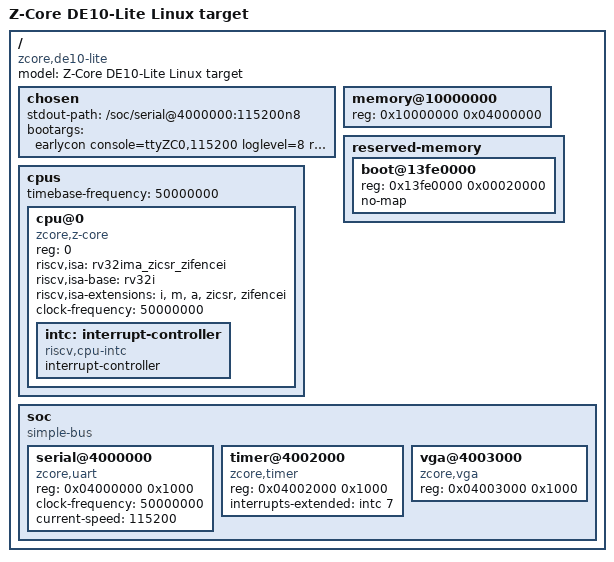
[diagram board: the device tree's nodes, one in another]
/dts-v1/;
/ {
	model = "Z-Core DE10-Lite Linux target";
	compatible = "zcore,de10-lite";
	#address-cells = <1>;
	#size-cells = <1>;
	chosen {
		stdout-path = "/soc/serial@4000000:115200n8";
		bootargs = "earlycon console=ttyZC0,115200 loglevel=8 rdinit=/init";
	};
	memory@10000000 { device_type = "memory"; reg = <0x10000000 0x04000000>; };
	reserved-memory {
		#address-cells = <1>;
		#size-cells = <1>;
		ranges;
		boot@13fe0000 { reg = <0x13fe0000 0x00020000>; no-map; };
	};
	cpus {
		#address-cells = <1>;
		#size-cells = <0>;
		timebase-frequency = <50000000>;
		cpu@0 {
			device_type = "cpu";
			compatible = "zcore,z-core", "riscv";
			reg = <0>;
			status = "okay";
			riscv,isa = "rv32ima_zicsr_zifencei";
			riscv,isa-base = "rv32i";
			riscv,isa-extensions = "i", "m", "a", "zicsr", "zifencei";
			clock-frequency = <50000000>;
			intc: interrupt-controller {
				compatible = "riscv,cpu-intc";
				interrupt-controller;
				#interrupt-cells = <1>;
				#address-cells = <0>;
			};
		};
	};
	soc {
		compatible = "simple-bus";
		#address-cells = <1>;
		#size-cells = <1>;
		ranges;
		serial@4000000 {
			compatible = "zcore,uart";
			reg = <0x04000000 0x1000>;
			clock-frequency = <50000000>;
			current-speed = <115200>;
		};
		timer@4002000 {
			compatible = "zcore,timer";
			reg = <0x04002000 0x1000>;
			interrupts-extended = <&intc 7>;
		};
		vga@4003000 {
			compatible = "zcore,vga";
			reg = <0x04003000 0x1000>;
		};
	};
};
